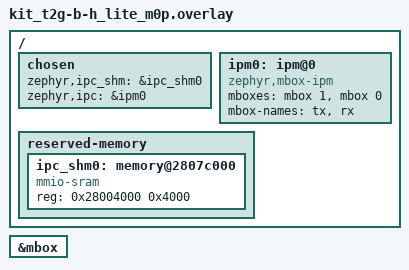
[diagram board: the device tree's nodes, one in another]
/*
 * Copyright (c) 2026 Infineon Technologies AG
 * SPDX-License-Identifier: Apache-2.0
 *
 * OpenAMP IPC overlay for kit_t2g-b-h_lite - Remote (M0P)
 */

/ {
	chosen {
		zephyr,ipc_shm = &ipc_shm0;
		zephyr,ipc = &ipm0;
	};

	ipm0: ipm@0 {
		compatible = "zephyr,mbox-ipm";
		mboxes = <&mbox 1>, <&mbox 0>;
		mbox-names = "tx", "rx";
		status = "okay";
	};

	reserved-memory {
		#address-cells = <1>;
		#size-cells = <1>;

		/*
		 * Shared memory region for IPC between M0P and CM7_0
		 * Must match the host overlay exactly
		 * Address: 0x28004000 (at end of M0P SRAM)
		 * Size: 16KB (0x4000)
		 */
		ipc_shm0: memory@2807c000 {
			compatible = "mmio-sram";
			reg = <0x28004000 0x4000>;
		};
	};
};

&mbox {
	status = "okay";
};
